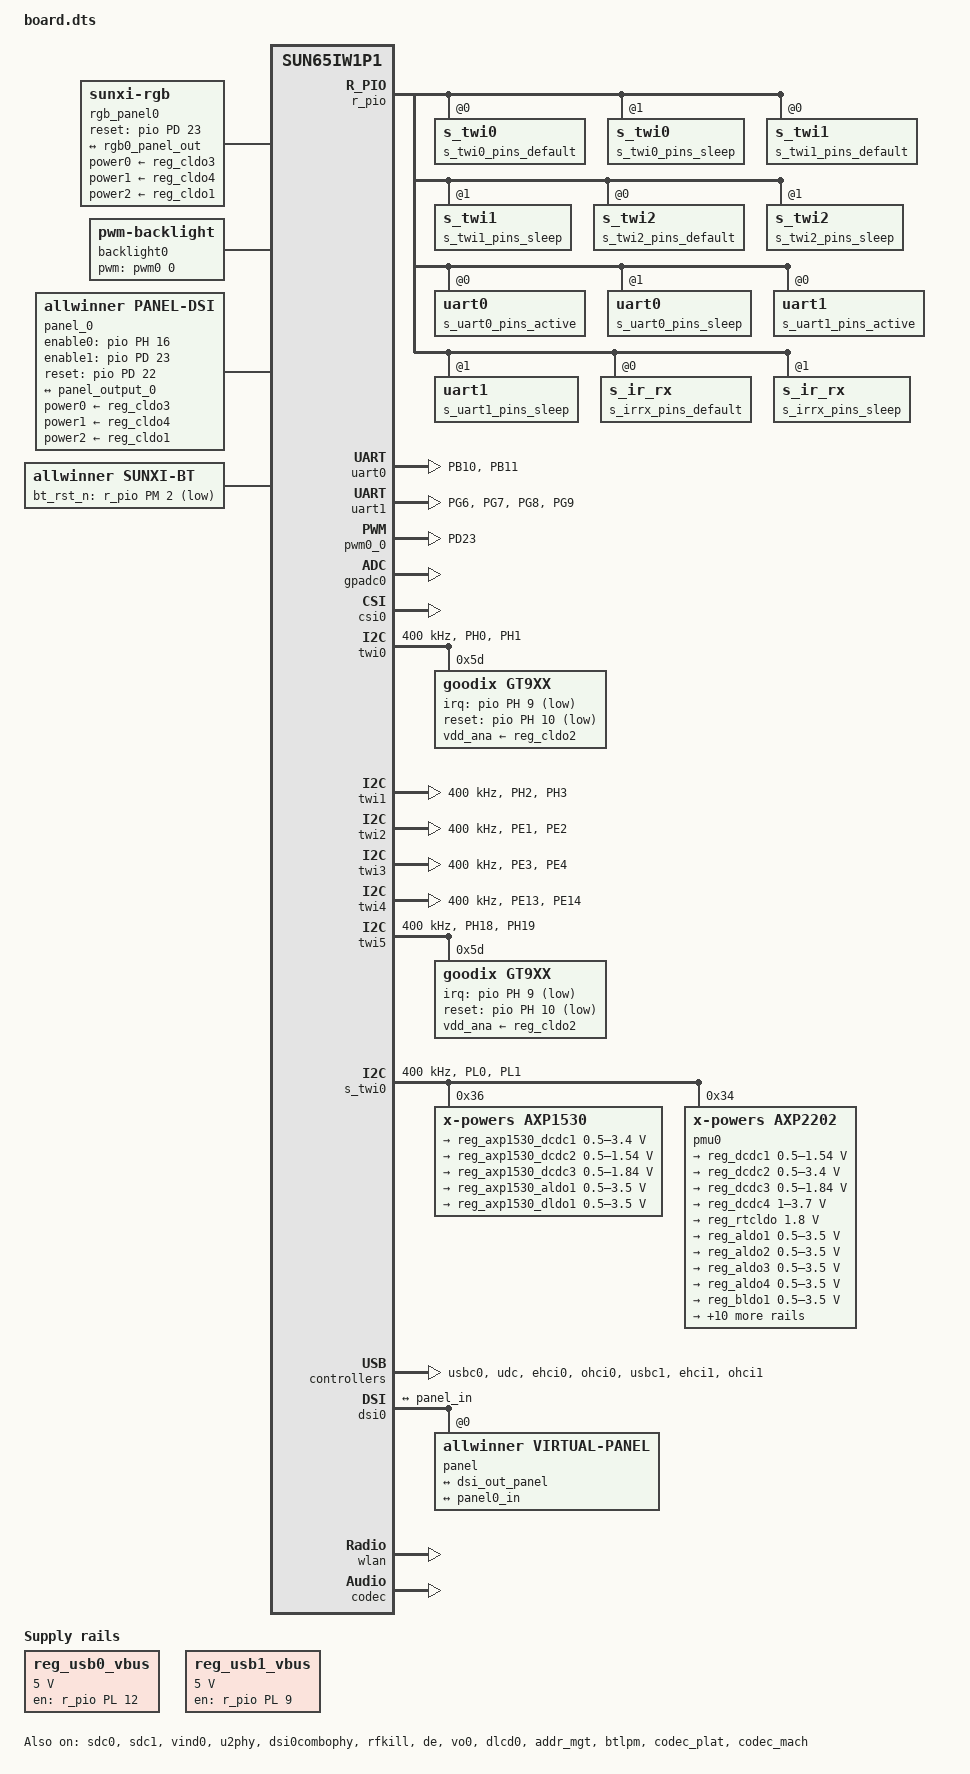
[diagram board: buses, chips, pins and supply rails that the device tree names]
// SPDX-License-Identifier: (GPL-2.0+ or MIT)

/dts-v1/;

#include "sun65iw1p1.dtsi"

/{
	board = "A537", "A537-EVB1";
	compatible = "allwinner,a537", "arm,sun65iw1p1";
	aliases {
	};

	cpus {
		/delete-node/ cpu@2;
		/delete-node/ cpu@3;
		/delete-node/ cpu@201;

		cpu-map {
			cluster0 {
				/delete-node/ core2;
				/delete-node/ core3;
			};

			cluster2 {
				/delete-node/ core1;
			};
		};
	};

	thermal-zones {
		/delete-node/ cpul_idle_zone;

		cpub_idle_zone {
			cooling-maps {
				map0 {
					cooling-device = <&cpu6_idle 0 100>;
				};
			};
		};
	};

	reg_usb0_vbus: usb0-vbus {
		compatible = "regulator-fixed";
		regulator-name = "usb0-vbus";
		regulator-min-microvolt = <5000000>;
		regulator-max-microvolt = <5000000>;
		regulator-enable-ramp-delay = <1000>;
		gpio = <&r_pio PL 12 GPIO_ACTIVE_HIGH>;
		enable-active-high;
	};

	reg_usb1_vbus: usb1-vbus {
		compatible = "regulator-fixed";
		regulator-name = "usb1-vbus";
		regulator-min-microvolt = <5000000>;
		regulator-max-microvolt = <5000000>;
		regulator-enable-ramp-delay = <1000>;
		gpio = <&r_pio PL 9 GPIO_ACTIVE_HIGH>;
		enable-active-high;
	};

	rgb_panel0: rgb_panel@0 {
		compatible = "sunxi-rgb";
		status = "okay";
		reg = <0>;
		power0-supply = <&reg_cldo3>;
		power1-supply = <&reg_cldo4>;
		power2-supply = <&reg_cldo1>;

//		backlight = <&rgb_panel_backlight>;
		reset-gpios = <&pio PD 23 GPIO_ACTIVE_HIGH>; //reset

		display-timings {
			native-mode = <&rgb_timing2>;

			rgb_timing0: timing0 {
				clock-frequency = <74871600>;
				hback-porch = <35>;
				hactive = <1024>;
				hfront-porch = <83>;
				hsync-len = <161>;
				vback-porch = <25>;
				vactive = <600>;
				vfront-porch = <15>;
				vsync-len = <10>;
			};
			rgb_timing1: timing1 {
				clock-frequency = <48360000>;
				hback-porch = <35>;
				hactive = <800>;
				hfront-porch = <385>;
				hsync-len = <20>;
				vback-porch = <25>;
				vactive = <480>;
				vfront-porch = <135>;
				vsync-len = <10>;
			};
			rgb_timing2: timing2 {
				clock-frequency = <29232000>;
				hback-porch = <40>;
				hactive = <800>;
				hfront-porch = <40>;
				hsync-len = <48>;
				vback-porch = <29>;
				vactive = <480>;
				vfront-porch = <13>;
				vsync-len = <3>;
			};
		};
		port {
			rgb0_panel_in: endpoint {
				remote-endpoint = <&rgb0_panel_out>;
			};
		};
	};

	backlight0: backlight0 {
		compatible = "pwm-backlight";
		status = "okay";
		brightness-levels = <
			  0   1   2   3   4   5   6   7
			  8   9  10  11  12  13  14  15
			 16  17  18  19  20  21  22  23
			 24  25  26  27  28  29  30  31
			 32  33  34  35  36  37  38  39
			 40  41  42  43  44  45  46  47
			 48  49  50  51  52  53  54  55
			 56  57  58  59  60  61  62  63
			 64  65  66  67  68  69  70  71
			 72  73  74  75  76  77  78  79
			 80  81  82  83  84  85  86  87
			 88  89  90  91  92  93  94  95
			 96  97  98  99 100 101 102 103
			104 105 106 107 108 109 110 111
			112 113 114 115 116 117 118 119
			120 121 122 123 124 125 126 127
			128 129 130 131 132 133 134 135
			136 137 138 139 140 141 142 143
			144 145 146 147 148 149 150 151
			152 153 154 155 156 157 158 159
			160 161 162 163 164 165 166 167
			168 169 170 171 172 173 174 175
			176 177 178 179 180 181 182 183
			184 185 186 187 188 189 190 191
			192 193 194 195 196 197 198 199
			200 201 202 203 204 205 206 207
			208 209 210 211 212 213 214 215
			216 217 218 219 220 221 222 223
			224 225 226 227 228 229 230 231
			232 233 234 235 236 237 238 239
			240 241 242 243 244 245 246 247
			248 249 250 251 252 253 254 255>;
		default-brightness-level = <73>;
		pwms = <&pwm0 0 25000 0>;
	};

	// lvds_panel: lvds_panel@0 {
	// 	compatible = "sunxi-lvds";
	// 	status = "disabled";
	// 	reg = <0>;
	// 	power0-supply = <&reg_cldo3>;
	// 	power1-supply = <&reg_cldo4>;
	// 	power2-supply = <&reg_cldo1>;
	// //	backlight = <&lvds_panel_backlight>;
	// 	bus-format = <MEDIA_BUS_FMT_RGB888_1X7X4_JEIDA>;
	// 	reset-gpios = <&pio PD 22 GPIO_ACTIVE_HIGH>; //reset
	// 	enable0-gpios = <&pio PH 14 GPIO_ACTIVE_HIGH>; //reset
	// 	display-timings {
	// 		native-mode = <&lvds_timing0>;

	// 		lvds_timing0: timing0 {
	// 			clock-frequency = <69255120>;
	// 			hback-porch = <18>;
	// 			hactive = <1280>;
	// 			hfront-porch = <117>;
	// 			hsync-len = <3>;
	// 			vback-porch = <7>;
	// 			vactive = <800>;
	// 			vfront-porch = <4>;
	// 			vsync-len = <3>;
	// 		};
	// 		lvds_timing1: timing1 {
	// 			clock-frequency = <148500000>;
	// 			hback-porch = <145>;
	// 			hactive = <1920>;
	// 			hfront-porch = <132>;
	// 			hsync-len = <3>;
	// 			vback-porch = <9>;
	// 			vactive = <1080>;
	// 			vfront-porch = <33>;
	// 			vsync-len = <3>;
	// 		};
	// 	};
	// 	port {
	// 		lvds_panel_in: endpoint {
	// 			remote-endpoint = <&lvds_panel_out>;
	// 		};
	// 	};
	// };

	panel_0: panel_0@0 {
		compatible = "allwinner,panel-dsi";
		status = "okay";
		power0-supply = <&reg_cldo3>;
		power1-supply = <&reg_cldo4>;
		power2-supply = <&reg_cldo1>;

		enable0-gpios = <&pio PH 16 GPIO_ACTIVE_HIGH>; // LCD-BL-EN
		enable1-gpios = <&pio PD 23 GPIO_ACTIVE_HIGH>; // LCD-BL-PWM
		reset-num = <2>;
		reset-delay-ms = <10>;
		reset-gpios = <&pio PD 22 GPIO_ACTIVE_HIGH>; // LCD-RST
		dsi,flags = <(MIPI_DSI_MODE_VIDEO | MIPI_DSI_SYNC_INCELL)>;
		dsi,lanes = <4>;
		dsi,format = <0>;
		panel-init-sequence = [
			05 78 01 11
			05 14 01 29
		];

		panel-exit-sequence = [
			05 00 01 28
			05 78 01 10
		];

		display-timings {
			native-mode = <&timing0>;

			timing0: timing0 {
				clock-frequency = <156408000>;
				hback-porch = <40>;
				hactive = <1200>;
				hfront-porch = <80>;
				hsync-len = <10>;
				vback-porch = <16>;
				vactive = <1920>;
				vfront-porch = <20>;
				vsync-len = <4>;

			};
		};
		port {
			panel0_in: endpoint {
				reg = <0>;
				remote-endpoint = <&panel_output_0>;
			};
		};
	};
};

&soc {
	arm_pmu {
		interrupts = <GIC_SPI 316 IRQ_TYPE_LEVEL_HIGH>,
				   <GIC_SPI 317 IRQ_TYPE_LEVEL_HIGH>,
				   <GIC_SPI 348 IRQ_TYPE_LEVEL_HIGH>,
				   <GIC_SPI 349 IRQ_TYPE_LEVEL_HIGH>,
				   <GIC_SPI 374 IRQ_TYPE_LEVEL_HIGH>;
		interrupt-affinity = <&cpu0>, <&cpu1>, <&cpu4>, <&cpu5>, <&cpu6>;
	};
};


&pio {
	uart0_pins_active: uart0_pins@0 {
		pins = "PB10", "PB11";
		function = "uart0";
	};

	uart0_pins_sleep: uart0_pins@1 {
		pins = "PB10", "PB11";
		function = "io_disabled";
	};

	uart1_pins_active: uart1_pins@0 {
		pins = "PG6", "PG7", "PG8", "PG9";
		function = "uart1";
	};

	uart1_pins_sleep: uart1_pins@1 {
		pins = "PG6", "PG7", "PG8", "PG9";
		function = "io_disabled";
	};

	uart2_pins_active: uart2_pins@0 {
		pins = "PB0", "PB1", "PB2", "PB3";
		function = "uart2";
	};

	uart2_pins_sleep: uart2_pins@1 {
		pins = "PB0", "PB1", "PB2", "PB3";
		function = "io_disabled";
	};

	uart3_pins_active: uart3_pins@0 {
		pins = "PH4", "PH5", "PH6", "PH7";
		function = "uart3";
	};

	uart3_pins_sleep: uart3_pins@1 {
		pins = "PH4", "PH5", "PH6", "PH7";
		function = "io_disabled";
	};

	uart4_pins_active: uart4_pins@0 {
		pins = "PE1", "PE2", "PE3", "PE4";
		function = "uart4";
	};

	uart4_pins_sleep: uart4_pins@1 {
		pins = "PE1", "PE2", "PE3", "PE4";
		function = "io_disabled";
	};

	uart5_pins_active: uart5_pins@0 {
		pins = "PE11", "PE12", "PE13", "PE14";
		function = "uart5";
	};

	uart5_pins_sleep: uart5_pins@1 {
		pins = "PE11", "PE12", "PE13", "PE14";
		function = "io_disabled";
	};

	uart6_pins_active: uart6_pins@0 {
		pins = "PH0", "PH1", "PH2", "PH3";
		function = "uart6";
	};

	uart6_pins_sleep: uart6_pins@1 {
		pins = "PH0", "PH1", "PH2", "PH3";
		function = "io_disabled";
	};

	uart7_pins_active: uart7_pins@0 {
		pins = "PE11", "PE12", "PE13", "PE14";
		function = "uart7";
	};

	uart7_pins_sleep: uart7_pins@1 {
		pins = "PE11", "PE12", "PE13", "PE14";
		function = "io_disabled";
	};

	twi0_pins_default: twi0@0 {
		pins = "PH0", "PH1";
		function = "twi0";
		drive-strength = <10>;
		bias-pull-up;
	};

	twi0_pins_sleep: twi0@1 {
		pins = "PH0", "PH1";
		function = "gpio_in";
	};

	twi1_pins_default: twi1@0 {
		pins = "PH2", "PH3";
		function = "twi1";
		drive-strength = <10>;
		bias-pull-up;
	};

	twi1_pins_sleep: twi1@1 {
		pins = "PH2", "PH3";
		function = "gpio_in";
	};

	twi2_pins_default: twi2@0 {
		pins = "PE1", "PE2";
		function = "twi2";
		drive-strength = <10>;
		bias-pull-up;
	};

	twi2_pins_sleep: twi2@1 {
		pins = "PE1", "PE2";
		function = "gpio_in";
	};

	twi3_pins_default: twi3@0 {
		pins = "PE3", "PE4";
		function = "twi3";
		drive-strength = <10>;
		bias-pull-up;
	};

	twi3_pins_sleep: twi3@1 {
		pins = "PE3", "PE4";
		function = "gpio_in";
	};

	twi4_pins_default: twi4@0 {
		pins = "PE13", "PE14";
		function = "twi4";
		drive-strength = <10>;
		bias-pull-up;
	};

	twi4_pins_sleep: twi4@1 {
		pins = "PE13", "PE14";
		function = "gpio_in";
	};

	twi5_pins_default: twi5@0 {
		pins = "PH18", "PH19";
		function = "twi5";
		drive-strength = <10>;
		bias-pull-up;
	};

	twi5_pins_sleep: twi5@1 {
		pins = "PH18", "PH19";
		function = "gpio_in";
	};

	pwm0_0_pins_active: pwm0@0 {
		pins = "PD23";
		function = "pwm0_0";
	};

	pwm0_0_pins_sleep: pwm0@1 {
		pins = "PD23";
		function = "gpio_in";
		bias-pull-down;
	};

	ledc_pins_active: ledc@0 {
		pins = "PH19";
		function = "ledc";
		drive-strength = <10>;
	};

	ledc_pins_sleep: ledc@1 {
		pins = "PH19";
		function = "gpio_in";
	};

	spi1_pins_default: spi1@0 {
		pins = "PD11", "PD12", "PD13"; /* clk, mosi, miso */
		function = "spi1";
		drive-strength = <10>;
	};

	spi1_pins_cs: spi1@1 {
		pins = "PD10"; /* cs */
		function = "spi1";
		drive-strength = <10>;
		bias-pull-up;
	};

	spi1_pins_sleep: spi1@2 {
		pins = "PD10", "PD11", "PD12", "PD13";
		function = "io_disabled";
	};

	irtx_pins_default: irtx@0 {
		pins = "PH18";
		function = "ir_tx";
	};

	irtx_pins_sleep: irtx@1 {
		pins = "PH18";
		function = "gpio_in";
	};

	irrx_pins_default: irrx@0 {
		pins = "PH19";
		function = "ir_rx";
	};

	irrx_pins_sleep: irrx@1 {
		pins = "PH19";
		function = "gpio_in";
	};

	owa_pins_a: owa@0 {
		pins = "PH7";
		function = "owa";
		drive-strength = <20>;
		bias-disable;
	};

	owa_pins_b: owa@1 {
		pins = "PH7";
		function = "io_disabled";
		drive-strength = <20>;
		bias-disable;
	};

	dmic_pins_a: dmic@0 {
		pins = "PH8", "PH9", "PH10", "PH11", "PH12";
		function = "dmic";
		drive-strength = <20>;
		bias-disable;
	};

	dmic_pins_b: dmic@1 {
		pins = "PH8", "PH9", "PH10", "PH11", "PH12";
		function = "io_disabled";
		drive-strength = <20>;
		bias-disable;
	};

	i2s0_pins_a: i2s0@0 {
		pins = "PB4";
		function = "i2s0_mclk";
		drive-strength = <20>;
		bias-disable;
	};

	i2s0_pins_b: i2s0@1 {
		pins = "PB5";
		function = "i2s0_bclk";
		drive-strength = <20>;
		bias-disable;
	};

	i2s0_pins_c: i2s0@2 {
		pins = "PB6";
		function = "i2s0_lrck";
		drive-strength = <20>;
		bias-disable;
	};

	i2s0_pins_d: i2s0@3 {
		pins = "PB8";
		function = "i2s0_din0";
		drive-strength = <20>;
		bias-disable;
	};

	i2s0_pins_e: i2s0@4 {
		pins = "PB4", "PB5", "PB6", "PB8";
		function = "io_disabled";
		drive-strength = <20>;
		bias-disable;
	};

};

&r_pio {
	s_twi0_pins_default: s_twi0@0 {
		pins = "PL0", "PL1";
		function = "s_twi0";
		drive-strength = <10>;
		bias-pull-up;
	};

	s_twi0_pins_sleep: s_twi0@1 {
		pins = "PL0", "PL1";
		function = "gpio_in";
	};

	s_twi1_pins_default: s_twi1@0 {
		pins = "PM2", "PM3";
		function = "s_twi1";
		drive-strength = <10>;
		bias-pull-up;
	};

	s_twi1_pins_sleep: s_twi1@1 {
		pins = "PM2", "PM3";
		function = "gpio_in";
	};

	s_twi2_pins_default: s_twi2@0 {
		pins = "PL12", "PL13";
		function = "s_twi2";
		drive-strength = <10>;
		bias-pull-up;
	};

	s_twi2_pins_sleep: s_twi2@1 {
		pins = "PL12", "PL13";
		function = "gpio_in";
	};

	s_uart0_pins_active: uart0@0 {
		pins = "PL2", "PL3";
		function = "s_uart0";
	};

	s_uart0_pins_sleep: uart0@1 {
		pins = "PL2", "PL3";
		function = "io_disabled";
	};

	s_uart1_pins_active: uart1@0 {
		pins = "PL14", "PL15";
		function = "s_uart1";
	};

	s_uart1_pins_sleep: uart1@1 {
		pins = "PL14", "PL15";
		function = "io_disabled";
	};

	s_irrx_pins_default: s_ir_rx@0 {
		pins = "PM5";
		function = "s_ir";
	};

	s_irrx_pins_sleep: s_ir_rx@1 {
		pins = "PM5";
		function = "gpio_in";
	};
};

&uart0 {
	pinctrl-names = "default", "sleep";
	pinctrl-0 = <&uart0_pins_active>;
	pinctrl-1 = <&uart0_pins_sleep>;
	status = "okay";
};

&uart1 {
	pinctrl-names = "default", "sleep";
	pinctrl-0 = <&uart1_pins_active>;
	pinctrl-1 = <&uart1_pins_sleep>;
	status = "okay";
};

&uart2 {
	pinctrl-names = "default", "sleep";
	pinctrl-0 = <&uart2_pins_active>;
	pinctrl-1 = <&uart2_pins_sleep>;
	status = "disabled";
};

&uart3 {
	pinctrl-names = "default", "sleep";
	pinctrl-0 = <&uart3_pins_active>;
	pinctrl-1 = <&uart3_pins_sleep>;
	status = "disabled";
};

&uart4 {
	pinctrl-names = "default", "sleep";
	pinctrl-0 = <&uart4_pins_active>;
	pinctrl-1 = <&uart4_pins_sleep>;
	status = "disabled";
};

&uart5 {
	pinctrl-names = "default", "sleep";
	pinctrl-0 = <&uart5_pins_active>;
	pinctrl-1 = <&uart5_pins_sleep>;
	status = "disabled";
};

&uart6 {
	pinctrl-names = "default", "sleep";
	pinctrl-0 = <&uart6_pins_active>;
	pinctrl-1 = <&uart6_pins_sleep>;
	status = "disabled";
};

&uart7 {
	pinctrl-names = "default", "sleep";
	pinctrl-0 = <&uart7_pins_active>;
	pinctrl-1 = <&uart7_pins_sleep>;
	status = "disabled";
};

&uart8 {
	pinctrl-names = "default", "sleep";
	pinctrl-0 = <&s_uart0_pins_active>;
	pinctrl-1 = <&s_uart0_pins_sleep>;
	status = "disabled";
};

&uart9 {
	pinctrl-names = "default", "sleep";
	pinctrl-0 = <&s_uart1_pins_active>;
	pinctrl-1 = <&s_uart1_pins_sleep>;
	status = "disabled";
};

&pwm0_0 {
	pinctrl-names = "active", "sleep";
	pinctrl-0 = <&pwm0_0_pins_active>;
	pinctrl-1 = <&pwm0_0_pins_sleep>;
	status = "okay";
};

&gpadc0 {
		channel_num = <5>;
		channel_select = <0x4>;
		channel_data_select = <0x4>;
		channel_compare_select = <0x4>;
		channel_cld_select = <0x4>;
		channel_chd_select = <0x4>;
		channel2_compare_lowdata = <1700000>;
		channel2_compare_higdata = <1200000>;
		status = "okay";
};

&ledc  {
        pinctrl-names = "default", "sleep";
        pinctrl-0 = <&ledc_pins_active>;
        pinctrl-1 = <&ledc_pins_sleep>;
        led_count = <32>;
        output_mode = "GRB";
        reset_ns = <84>;
        t1h_ns = <800>;
        t1l_ns = <320>;
        t0h_ns = <300>;
        t0l_ns = <800>;
        wait_time0_ns = <84>;
        wait_time1_ns = <84>;
        wait_data_time_ns = <600000>;
        status = "disabled";
};

&sdc2 {
	fixed-emmc-driver-type = <2>;
	non-removable;
	bus-width = <8>;
	mmc-ddr-1_8v;
	mmc-hs200-1_8v;
	mmc-hs400-1_8v;
	no-sdio;
	no-sd;
	ctl-spec-caps = <0x328>;
	cap-mmc-highspeed;
	sunxi-dis-signal-vol-sw;
	mmc-bootpart-noacc;
	/*cap-hsq;*/
	cqe-on;
	ctl-cmdq-md = <0x2>;
	max-frequency = <200000000>;
	vmmc-supply = <&reg_cldo3>;
	/*emmc io vol 1.8v*/
	vqmmc-supply = <&reg_cldo1>;
	status = "disabled";
};

&sdc0 {
	bus-width = <4>;
	cd-gpios = <&pio PF 6 (GPIO_ACTIVE_LOW | GPIO_PULL_UP)>;
	/*non-removable;*/
	/*broken-cd;*/
	/*cd-inverted*/
	/*data3-detect;*/
	/*card-pwr-gpios = <&pio PH 14 1 1 2 0xffffffff>;*/
	cd-used-24M;
	cd-set-debounce = <0x1>;
	cap-sd-highspeed;
	sd-uhs-sdr50;
	sd-uhs-ddr50;
	sd-uhs-sdr104;
	no-sdio;
	no-mmc;
	sunxi-power-save-mode;
	/*sunxi-dis-signal-vol-sw;*/
	max-frequency = <150000000>;
	ctl-spec-caps = <0x428>;
	vmmc-supply = <&reg_cldo3>;
	vqmmc33sw-supply = <&reg_cldo3>;
	vdmmc33sw-supply = <&reg_cldo3>;
	vqmmc18sw-supply = <&reg_cldo1>;
	vdmmc18sw-supply = <&reg_cldo1>;
	status = "okay";
};

&sdc1 {
	bus-width = <4>;
	no-mmc;
	no-sd;
	cap-sd-highspeed;
	/*sd-uhs-sdr12*/
	sd-uhs-sdr25;
	sd-uhs-sdr50;
	sd-uhs-ddr50;
	sd-uhs-sdr104;
	/*sunxi-power-save-mode;*/
	sunxi-dis-signal-vol-sw;
	cap-sdio-irq;
	keep-power-in-suspend;
	ignore-pm-notify;
	/*
	 * For AIC Wi-Fi SDIO3.0,
	 * when max-frequency = <208000000>, set sunxi-dly-208M = <0 0 0 0 0 0>
	 * when max-frequency = <150000000>, set sunxi-dly-208M = <1 1 0 0 1 1>
	 */
	max-frequency = <208000000>;
	sunxi-dly-208M  = <0 0 0 0 0 0>;
	ctl-spec-caps = <0x428>;
	status = "okay";
};

&vind0 {
	csi_top = <540000000>;
	csi_isp = <504000000>;
	vind_mclkpin-supply = <&reg_aldo2>; /* vcc-pe */
	vind_mclkpin_vol = <1800000>;
	vind_mcsipin-supply = <&reg_cldo1>; /* vcc-pk */
	vind_mcsipin_vol = <1800000>;
	vind_mipipin-supply = <&reg_cldo1>; /* vcc-mcsi */
	vind_mipipin_vol = <1800000>;

	status = "okay";

	csi0: csi@4820000  {
		pinctrl-0 = <>;
		pinctrl-1 = <>;
		status = "okay";
	};

	tdm0: tdm@4908000 {
		work_mode = <1>;
	};

	isp00:isp@4900000 {
		work_mode = <1>;
	};

	isp01:isp@48ffffc {
		status = "okay";
	};

	isp02:isp@48ffff8 {
		status = "disabled";
	};

	isp03:isp@48ffff4 {
		status = "disabled";
	};

	isp10:isp@4 {
		status = "disabled";
	};

	isp20:isp@5 {
		status = "disabled";
	};

	isp30:isp@6 {
		status = "disabled";
	};

	scaler00:scaler@4910000 {
		work_mode = <1>;
	};

	scaler01:scaler@490fffc {
		status = "okay";
	};

	scaler02:scaler@490fff8 {
		status = "okay";
	};

	scaler03:scaler@490fff4 {
		status = "disabled";
	};

	scaler10:scaler@4910400 {
		work_mode = <1>;
	};

	scaler11:scaler@49103fc {
		status = "okay";
	};

	scaler12:scaler@49103f8 {
		status = "okay";
	};

	scaler13:scaler@49103f4 {
		status = "disabled";
	};

	scaler20:scaler@4910800 {
		work_mode = <1>;
	};

	scaler21:scaler@49107fc {
		status = "disabled";
	};

	scaler22:scaler@49107f8 {
		status = "disabled";
	};

	scaler23:scaler@49107f4 {
		status = "disabled";
	};

	scaler30:scaler@4910c00 {
		work_mode = <1>;
	};

	scaler31:scaler@4910bfc {
		status = "disabled";
	};

	scaler32:scaler@4910bf8 {
		status = "disabled";
	};

	scaler33:scaler@4910bf4 {
		status = "disabled";
	};

	actuator0: actuator@2108180 {
		device_type = "actuator0";
		actuator0_name = "cn3927_act";
		actuator0_slave = <0x18>;
		actuator0_af_pwdn = <>;
		actuator0_afvdd = "afvcc-csi";
		actuator0_afvdd_vol = <2800000>;
		status = "okay";
	};

	flash0: flash@2108190 {
		device_type = "flash0";
		flash0_type = <2>;
		flash0_en = <&r_pio PL 8 GPIO_ACTIVE_LOW>;
		flash0_mode = <>;
		flash0_flvdd = "";
		flash0_flvdd_vol = <>;
		device_id = <0>;
		status = "disabled";
	};

	sensor0: sensor@4812000 {
		device_type = "sensor0";
		sensor0_mname = "ov8856_mipi_2";
		sensor0_twi_cci_id = <2>;
		sensor0_twi_addr = <0x6c>;
		sensor0_mclk_id = <0>;
		sensor0_pos = "rear";
		sensor0_isp_used = <1>;
		sensor0_fmt = <1>;
		sensor0_stby_mode = <0>;
		sensor0_vflip = <0>;
		sensor0_hflip = <0>;
		sensor0_cameravdd-supply = <&reg_bldo3>;
		sensor0_cameravdd_vol = <2800000>;
		sensor0_iovdd-supply = <&reg_aldo2>;
		sensor0_iovdd_vol = <1800000>;
		sensor0_avdd-supply = <&reg_aldo1>;
		sensor0_avdd_vol = <2800000>;
		sensor0_dvdd-supply = <&reg_bldo4>;
		sensor0_dvdd_vol = <1200000>;
		sensor0_power_en = <>;
		sensor0_reset = <&pio PE 9 GPIO_ACTIVE_LOW>;
		sensor0_pwdn = <&pio PE 8 GPIO_ACTIVE_LOW>;
		status = "okay";
	};

	sensor1: sensor@4812010 {
		device_type = "sensor1";
		sensor1_mname = "gc6153";
		sensor1_twi_cci_id = <3>;
		sensor1_twi_addr = <0x80>;
		sensor1_mclk_id = <1>;
		sensor1_pos = "rear";
		sensor1_isp_used = <1>;
		sensor1_fmt = <1>;
		sensor1_stby_mode = <0>;
		sensor1_vflip = <0>;
		sensor1_hflip = <0>;
		sensor1_iovdd-supply = <&reg_aldo2>;
		sensor1_iovdd_vol = <1800000>;
		sensor1_avdd-supply = <&reg_aldo1>;
		sensor1_avdd_vol = <2800000>;
		sensor1_dvdd-supply = <&reg_bldo4>;
		sensor1_dvdd_vol = <1200000>;
		sensor1_power_en = <>;
		sensor1_reset = <&pio PE 12 GPIO_ACTIVE_LOW>;
		sensor1_pwdn = <&pio PE 11 GPIO_ACTIVE_LOW>;
		status = "disabled";
	};

	sensor2: sensor@4812020 {
		device_type = "sensor2";
		sensor2_mname = "gc05a2_mipi";
		sensor2_twi_cci_id = <2>;
		sensor2_twi_addr = <0x6e>;
		sensor2_mclk_id = <0>;
		sensor2_pos = "front";
		sensor2_isp_used = <1>;
		sensor2_fmt = <1>;
		sensor2_stby_mode = <0>;
		sensor2_vflip = <0>;
		sensor2_hflip = <0>;
		sensor2_iovdd-supply = <&reg_aldo2>;
		sensor2_iovdd_vol = <1800000>;
		sensor2_avdd-supply = <&reg_aldo1>;
		sensor2_avdd_vol = <2800000>;
		sensor2_dvdd-supply = <&reg_bldo4>;
		sensor2_dvdd_vol = <1200000>;
		sensor2_power_en = <>;
		sensor2_reset = <&pio PE 7 GPIO_ACTIVE_LOW>;
		sensor2_pwdn = <&pio PE 6 GPIO_ACTIVE_LOW>;
		status = "okay";
	};

	sensor_list0:sensor_list@4812040 {
		sensor00_mname = "ov8856_mipi_2";
		sensor00_twi_addr = <0x6c>;
		sensor00_type = <1>;
		sensor00_hflip =  <0>;
		sensor00_vflip = <0>;
		sensor00_act_used = <1>;
		sensor00_act_name = "cn3927_act";
		sensor00_act_twi_addr = <0x18>;
		sensor01_mname = "ov13b10_mipi";
		sensor01_twi_addr = <0x6c>;
		sensor01_type = <1>;
		sensor01_hflip = <0>;
		sensor01_vflip = <0>;
		sensor01_act_used = <1>;
		sensor01_act_name = "cn3927_act";
		sensor01_act_twi_addr = <0x18>;
		sensor02_mname = "";
		sensor02_twi_addr = <>;
		sensor02_type = <>;
		sensor02_hflip =  <>;
		sensor02_vflip = <>;
		sensor02_act_used = <>;
		sensor02_act_name = "";
		sensor02_act_twi_addr = <>;
		status = "okay";
	};

	sensor_list1:sensor_list@4812050 {
		sensor10_mname = "gc6153";
		sensor10_twi_addr = <0x80>;
		sensor10_type = <1>;
		sensor10_hflip =  <0>;
		sensor10_vflip = <0>;
		sensor10_act_used = <0>;
		sensor10_act_name = "";
		sensor10_act_twi_addr = <>;
		sensor11_mname = "";
		sensor11_twi_addr = <>;
		sensor11_type = <>;
		sensor11_hflip =  <>;
		sensor11_vflip = <>;
		sensor11_act_used = <>;
		sensor11_act_name = "";
		sensor11_act_twi_addr = <>;
		sensor12_mname = "";
		sensor12_twi_addr = <>;
		sensor12_type = <>;
		sensor12_hflip =  <>;
		sensor12_vflip = <>;
		sensor12_act_used = <>;
		sensor12_act_name = "";
		sensor12_act_twi_addr = <>;
		status = "disabled";
	};

	sensor_list2:sensor_list@4812060 {
		reg = <0x0 0x04812060 0x0 0x10>;
		device_type = "sensor_list2";
		compatible = "allwinner,sunxi-sensor-list";
		csi_sel = <0>;
		sensor20_mname = "gc05a2_mipi";
		sensor20_twi_addr = <0x6e>;
		sensor20_type = <1>;
		sensor20_hflip =  <0>;
		sensor20_vflip = <0>;
		sensor20_act_used = <0>;
		sensor20_act_name = "";
		sensor20_act_twi_addr = <>;
		sensor21_mname = "";
		sensor21_twi_addr = <>;
		sensor21_type = <>;
		sensor21_hflip =  <>;
		sensor21_vflip = <>;
		sensor21_act_used = <>;
		sensor21_act_name = "";
		sensor21_act_twi_addr = <>;
		sensor22_mname = "";
		sensor22_twi_addr = <>;
		sensor22_type = <>;
		sensor22_hflip =  <>;
		sensor22_vflip = <>;
		sensor22_act_used = <>;
		sensor22_act_name = "";
		sensor22_act_twi_addr = <>;
		device_id = <1>;
		status = "okay";
	};

	vinc00:vinc@4830000 {
		vinc0_csi_sel = <0>;
		vinc0_mipi_sel = <0>;
		vinc0_isp_sel = <0>;
		vinc0_isp_tx_ch = <0>;
		vinc0_tdm_rx_sel = <0>;
		vinc0_rear_sensor_sel = <0>;
		vinc0_front_sensor_sel = <0>;
		vinc0_sensor_list = <1>;
		device_id = <0>;
		work_mode = <0x1>;
		status = "okay";
	};

	vinc01:vinc@482fffc {
		vinc1_csi_sel = <0>;
		vinc1_mipi_sel = <0>;
		vinc1_isp_sel = <1>;
		vinc1_isp_tx_ch = <0>;
		vinc1_tdm_rx_sel = <1>;
		vinc1_rear_sensor_sel = <0>;
		vinc1_front_sensor_sel = <0>;
		vinc1_sensor_list = <1>;
		device_id = <1>;
		status = "okay";
	};

	vinc02:vinc@482fff8 {
		vinc2_csi_sel = <2>;
		vinc2_mipi_sel = <2>;
		vinc2_isp_sel = <2>;
		vinc2_isp_tx_ch = <0>;
		vinc2_tdm_rx_sel = <2>;
		vinc2_rear_sensor_sel = <1>;
		vinc2_front_sensor_sel = <1>;
		vinc2_sensor_list = <1>;
		device_id = <2>;
		status = "disabled";
	};

	vinc03:vinc@482fff4 {
		vinc3_csi_sel = <0>;
		vinc3_mipi_sel = <0xff>;
		vinc3_isp_sel = <0>;
		vinc3_isp_tx_ch = <0>;
		vinc3_tdm_rx_sel = <0>;
		vinc3_rear_sensor_sel = <1>;
		vinc3_front_sensor_sel = <1>;
		vinc3_sensor_list = <0>;
		device_id = <3>;
		status = "disabled";
	};

	vinc10:vinc@4831000 {
		vinc4_csi_sel = <0>;
		vinc4_mipi_sel = <0>;
		vinc4_isp_sel = <0>;
		vinc4_isp_tx_ch = <0>;
		vinc4_tdm_rx_sel = <0>;
		vinc4_rear_sensor_sel = <0>;
		vinc4_front_sensor_sel = <0>;
		vinc4_sensor_list = <1>;
		device_id = <4>;
		work_mode = <0x1>;
		status = "okay";
	};

	vinc11:vinc@4830ffc {
		vinc5_csi_sel = <0>;
		vinc5_mipi_sel = <0>;
		vinc5_isp_sel = <1>;
		vinc5_isp_tx_ch = <0>;
		vinc5_tdm_rx_sel = <1>;
		vinc5_rear_sensor_sel = <0>;
		vinc5_front_sensor_sel = <0>;
		vinc5_sensor_list = <1>;
		device_id = <5>;
		status = "okay";
	};

	vinc12:vinc@4830ff8 {
		vinc6_csi_sel = <2>;
		vinc6_mipi_sel = <2>;
		vinc6_isp_sel = <2>;
		vinc6_isp_tx_ch = <0>;
		vinc6_tdm_rx_sel = <2>;
		vinc6_rear_sensor_sel = <1>;
		vinc6_front_sensor_sel = <1>;
		vinc6_sensor_list = <1>;
		device_id = <6>;
		status = "disabled";
	};

	vinc13:vinc@4830ff4 {
		vinc7_csi_sel = <2>;
		vinc7_mipi_sel = <0xff>;
		vinc7_isp_sel = <0>;
		vinc7_isp_tx_ch = <0>;
		vinc7_tdm_rx_sel = <0>;
		vinc7_rear_sensor_sel = <0>;
		vinc7_front_sensor_sel = <0>;
		vinc7_sensor_list = <0>;
		device_id = <7>;
		status = "disabled";
	};

	vinc20:vinc@4832000 {
		vinc8_csi_sel = <1>;
		vinc8_mipi_sel = <1>;
		vinc8_isp_sel = <0>;
		vinc8_isp_tx_ch = <0>;
		vinc8_tdm_rx_sel = <0>;
		vinc8_rear_sensor_sel = <2>;
		vinc8_front_sensor_sel = <2>;
		vinc8_sensor_list = <1>;
		device_id = <8>;
		work_mode = <0x1>;
		status = "okay";
	};

	vinc21:vinc@4831ffc {
		vinc9_csi_sel = <2>;
		vinc9_mipi_sel = <0xff>;
		vinc9_isp_sel = <0>;
		vinc9_isp_tx_ch = <0>;
		vinc9_tdm_rx_sel = <0>;
		vinc9_rear_sensor_sel = <0>;
		vinc9_front_sensor_sel = <0>;
		vinc9_sensor_list = <0>;
		device_id = <9>;
		status = "disabled";
	};

	vinc22:vinc@4831ff8 {
		vinc10_csi_sel = <2>;
		vinc10_mipi_sel = <0xff>;
		vinc10_isp_sel = <0>;
		vinc10_isp_tx_ch = <0>;
		vinc10_tdm_rx_sel = <0>;
		vinc10_rear_sensor_sel = <0>;
		vinc10_front_sensor_sel = <0>;
		vinc10_sensor_list = <0>;
		device_id = <10>;
		status = "disabled";
	};

	vinc23:vinc@4831ff4 {
		vinc11_csi_sel = <2>;
		vinc11_mipi_sel = <0xff>;
		vinc11_isp_sel = <0>;
		vinc11_isp_tx_ch = <0>;
		vinc11_tdm_rx_sel = <0>;
		vinc11_rear_sensor_sel = <0>;
		vinc11_front_sensor_sel = <0>;
		vinc11_sensor_list = <0>;
		device_id = <11>;
		status = "disabled";
	};

	vinc30:vinc@4833000 {
		vinc12_csi_sel = <1>;
		vinc12_mipi_sel = <1>;
		vinc12_isp_sel = <0>;
		vinc12_isp_tx_ch = <0>;
		vinc12_tdm_rx_sel = <0>;
		vinc12_rear_sensor_sel = <2>;
		vinc12_front_sensor_sel = <2>;
		vinc12_sensor_list = <1>;
		device_id = <12>;
		work_mode = <0x1>;
		status = "okay";
	};

	vinc31:vinc@4832ffc {
		vinc13_csi_sel = <2>;
		vinc13_mipi_sel = <0xff>;
		vinc13_isp_sel = <0>;
		vinc13_isp_tx_ch = <0>;
		vinc13_tdm_rx_sel = <0>;
		vinc13_rear_sensor_sel = <0>;
		vinc13_front_sensor_sel = <0>;
		vinc13_sensor_list = <0>;
		device_id = <13>;
		status = "disabled";
	};

	vinc32:vinc@4832ff8 {
		vinc14_csi_sel = <2>;
		vinc14_mipi_sel = <0xff>;
		vinc14_isp_sel = <0>;
		vinc14_isp_tx_ch = <0>;
		vinc14_tdm_rx_sel = <0>;
		vinc14_rear_sensor_sel = <0>;
		vinc14_front_sensor_sel = <0>;
		vinc14_sensor_list = <0>;
		device_id = <14>;
		status = "disabled";
	};

	vinc33:vinc@4832ff4 {
		vinc15_csi_sel = <2>;
		vinc15_mipi_sel = <0xff>;
		vinc15_isp_sel = <0>;
		vinc15_isp_tx_ch = <0>;
		vinc15_tdm_rx_sel = <0>;
		vinc15_rear_sensor_sel = <0>;
		vinc15_front_sensor_sel = <0>;
		vinc15_sensor_list = <0>;
		device_id = <15>;
		status = "disabled";
	};
};

&twi0 {
	clock-frequency = <400000>;
	pinctrl-0 = <&twi0_pins_default>;
	pinctrl-1 = <&twi0_pins_sleep>;
	pinctrl-names = "default", "sleep";
	/* For stability and backwards compatibility, we recommend setting 'twi_drv_used' to 1 */
	twi_drv_used = <1>;
	/* twi-supply = <&reg_cldo3>; */
	status = "okay";

	ac107: ac107@36 {
		#sound-dai-cells        = <0>;
		compatible              = "allwinner,sunxi-ac107";
		reg                     = <0x36>;
		pllclk-src              = "MCLK";
		sysclk-src              = "MCLK";
		pcm-bit-first           = "MSB";
		frame-sync-width        = <1>;
		tx-pin-chmap0           = <0x10101010>;
		tx-pin-chmap1           = <0x10101010>;
		ch1-dig-vol             = <160>;
		ch2-dig-vol             = <160>;
		ch1-pga-gain            = <26>;
		ch2-pga-gain            = <26>;
		status                  = "disabled";
	};

	gt9xx {
		compatible = "goodix,gt9xx";
		reg = <0x5d>;
		status = "okay";
		irq-gpios = <&pio PH 9 GPIO_ACTIVE_LOW>;
		irq-flags = <2>;
		reset-gpios = <&pio PH 10 GPIO_ACTIVE_LOW>;
		vdd_ana-supply = <&reg_cldo2>;

		touchscreen-max-id = <11>;
		touchscreen-size-x = <1200>;
		touchscreen-size-y = <1920>;
		touchscreen-max-w = <512>;
		touchscreen-max-p = <512>;
		//touchscreen-key-map = <172>, <158>; /*KEY_HOMEPAGE=172, KEY_BACK=158，KEY_MENU=139*/
		goodix,slide-wakeup = <0>;
		goodix,type-a-report = <1>;
		goodix,driver-send-cfg = <0>;
		goodix,send-cfg-id = <0>;
		goodix,resume-in-workqueue = <0>;
		goodix,int-sync = <1>;
		goodix,revert_x = <1>;
		goodix,revert_y = <1>;
		goodix,swap-x2y = <0>;
		goodix,tp_idle_support = <1>;
		goodix,esd-protect = <1>;
		goodix,auto-update-cfg = <0>;
		goodix,power-off-sleep = <1>;
		goodix,pen-suppress-finger = <0>;
		/* GT9271_Config_20221222_v67.cfg*/
		goodix,cfg-group0 = [
			43 B0 04 80 07 0A 35 00 01 08
			28 0F 50 32 03 05 00 00 00 00
			00 00 00 17 19 1B 14 90 2B 99
			2F 31 8E 12 00 00 00 DA 03 10
			00 00 00 00 00 00 00 00 00 11
			00 29 4B 94 C5 02 07 00 00 04
			85 2B 00 7D 31 00 77 37 00 72
			3E 00 6F 46 00 6F 00 00 00 00
			00 00 00 00 00 00 00 00 00 00
			00 00 00 00 00 00 00 00 00 00
			00 00 00 00 C0 00 00 00 00 00
			00 00 17 16 15 14 11 10 0F 0E
			0D 0C 09 08 07 06 05 04 01 00
			FF FF FF FF FF FF 00 00 00 00
			00 00 25 24 23 22 21 20 1F 1E
			1C 1B 19 14 13 12 11 10 0F 0E
			0D 0C 0A 08 07 06 04 02 00 FF
			FF FF FF FF 00 00 00 00 00 00
			00 00 00 00 73 01
		];
	};
};

&twi1 {
	clock-frequency = <400000>;
	pinctrl-0 = <&twi1_pins_default>;
	pinctrl-1 = <&twi1_pins_sleep>;
	pinctrl-names = "default", "sleep";
	/* For stability and backwards compatibility, we recommend setting 'twi_drv_used' to 1 */
	twi_drv_used = <1>;
	/* twi-supply = <&reg_cldo3>; */
	status = "okay";
};

&twi2 {
	clock-frequency = <400000>;
	pinctrl-0 = <&twi2_pins_default>;
	pinctrl-1 = <&twi2_pins_sleep>;
	pinctrl-names = "default", "sleep";
	/* For stability and backwards compatibility, we recommend setting 'twi_drv_used' to 1 */
	twi_drv_used = <1>;
	/* twi-supply = <&reg_aldo2>; */
	status = "okay";
};

&twi3 {
	clock-frequency = <400000>;
	pinctrl-0 = <&twi3_pins_default>;
	pinctrl-1 = <&twi3_pins_sleep>;
	pinctrl-names = "default", "sleep";
	/* For stability and backwards compatibility, we recommend setting 'twi_drv_used' to 1 */
	twi_drv_used = <1>;
	/* twi-supply = <&reg_aldo2>; */
	status = "okay";
};

&twi4 {
	clock-frequency = <400000>;
	pinctrl-0 = <&twi4_pins_default>;
	pinctrl-1 = <&twi4_pins_sleep>;
	pinctrl-names = "default", "sleep";
	/* For stability and backwards compatibility, we recommend setting 'twi_drv_used' to 1 */
	twi_drv_used = <1>;
	/* twi-supply = <&reg_aldo2>; */
	status = "okay";
};

&twi5 {
	clock-frequency = <400000>;
	pinctrl-0 = <&twi5_pins_default>;
	pinctrl-1 = <&twi5_pins_sleep>;
	pinctrl-names = "default", "sleep";
	/* For stability and backwards compatibility, we recommend setting 'twi_drv_used' to 1 */
	twi_drv_used = <1>;
	twi-supply = <&reg_cldo3>;
	status = "okay";

	gt9xx {
		compatible = "goodix,gt9xx";
		reg = <0x5d>;
		status = "okay";
		irq-gpios = <&pio PH 9 GPIO_ACTIVE_LOW>;
		irq-flags = <2>;
		reset-gpios = <&pio PH 10 GPIO_ACTIVE_LOW>;
		vdd_ana-supply = <&reg_cldo2>;

		touchscreen-max-id = <11>;
		touchscreen-size-x = <1200>;
		touchscreen-size-y = <1920>;
		touchscreen-max-w = <512>;
		touchscreen-max-p = <512>;
		//touchscreen-key-map = <172>, <158>; /*KEY_HOMEPAGE=172, KEY_BACK=158，KEY_MENU=139*/
		goodix,slide-wakeup = <0>;
		goodix,type-a-report = <1>;
		goodix,driver-send-cfg = <0>;
		goodix,send-cfg-id = <0>;
		goodix,resume-in-workqueue = <0>;
		goodix,int-sync = <1>;
		goodix,revert_x = <1>;
		goodix,revert_y = <1>;
		goodix,swap-x2y = <0>;
		goodix,tp_idle_support = <1>;
		goodix,esd-protect = <1>;
		goodix,auto-update-cfg = <0>;
		goodix,power-off-sleep = <1>;
		goodix,pen-suppress-finger = <0>;
		/* GT9271_Config_20221222_v67.cfg*/
		goodix,cfg-group0 = [
			43 B0 04 80 07 0A 35 00 01 08
			28 0F 50 32 03 05 00 00 00 00
			00 00 00 17 19 1B 14 90 2B 99
			2F 31 8E 12 00 00 00 DA 03 10
			00 00 00 00 00 00 00 00 00 11
			00 29 4B 94 C5 02 07 00 00 04
			85 2B 00 7D 31 00 77 37 00 72
			3E 00 6F 46 00 6F 00 00 00 00
			00 00 00 00 00 00 00 00 00 00
			00 00 00 00 00 00 00 00 00 00
			00 00 00 00 C0 00 00 00 00 00
			00 00 17 16 15 14 11 10 0F 0E
			0D 0C 09 08 07 06 05 04 01 00
			FF FF FF FF FF FF 00 00 00 00
			00 00 25 24 23 22 21 20 1F 1E
			1C 1B 19 14 13 12 11 10 0F 0E
			0D 0C 0A 08 07 06 04 02 00 FF
			FF FF FF FF 00 00 00 00 00 00
			00 00 00 00 73 01
		];
	};

};

&s_twi0 {
	clock-frequency = <400000>;
	pinctrl-0 = <&s_twi0_pins_default>;
	pinctrl-1 = <&s_twi0_pins_sleep>;
	pinctrl-names = "default", "sleep";
	/* For stability and backwards compatibility, we recommend setting 'twi_drv_used' to 1 */
	twi_drv_used = <1>;
	/* twi-supply = <&reg_aldo3>; */
	no_suspend = <1>;
	status = "okay";

	axp1530: axp1530@36{
		compatible = "x-powers,axp1530";
		status = "okay";
		reg = <0x36>;

		powerkey1: powerkey@1 {
			status = "disabled";
			compatible = "x-powers,axp1530-pek";
		};

		regulators{
			compatible = "x-powers,axp1530-regulator";
			reg_axp1530_dcdc1: dcdc1 {
				regulator-name = "axp1530-dcdc1";
				regulator-min-microvolt = <500000>;
				regulator-max-microvolt = <3400000>;
				regulator-step-delay-us = <25>;
				regulator-final-delay-us = <50>;
				regulator-always-on;
			};

			reg_axp1530_dcdc2: dcdc2 {
				regulator-name = "axp1530-dcdc2";
				regulator-min-microvolt = <500000>;
				regulator-max-microvolt = <1540000>;
				regulator-step-delay-us = <25>;
				regulator-final-delay-us = <50>;
				regulator-always-on;
			};

			reg_axp1530_dcdc3: dcdc3 {
				regulator-name = "axp1530-dcdc3";
				regulator-min-microvolt = <500000>;
				regulator-max-microvolt = <1840000>;
				regulator-step-delay-us = <25>;
				regulator-final-delay-us = <50>;
			};

			reg_axp1530_aldo1: ldo1 {
				regulator-name = "axp1530-aldo1";
				regulator-min-microvolt = <500000>;
				regulator-max-microvolt = <3500000>;
				regulator-step-delay-us = <25>;
				regulator-final-delay-us = <50>;
			};

			reg_axp1530_dldo1: ldo2 {
				regulator-name = "axp1530-dldo1";
				regulator-min-microvolt = <500000>;
				regulator-max-microvolt = <3500000>;
				regulator-step-delay-us = <25>;
				regulator-final-delay-us = <50>;
			};
		};
		virtual-ext-dcdc1 {
			compatible = "xpower-vregulator,dcdc1";
			dcdc1-supply = <&reg_axp1530_dcdc1>;
		};
		virtual-ext-dcdc2 {
			compatible = "xpower-vregulator,dcdc2";
			dcdc2-supply = <&reg_axp1530_dcdc2>;
		};
		virtual-ext-dcdc3 {
			compatible = "xpower-vregulator,dcdc3";
			dcdc3-supply = <&reg_axp1530_dcdc3>;
		};
		virtual-ext-aldo1 {
			compatible = "xpower-vregulator,aldo1";
			aldo1-supply = <&reg_axp1530_aldo1>;
		};
		virtual-ext-dldo1 {
			compatible = "xpower-vregulator,dldo1";
			dldo1-supply = <&reg_axp1530_dldo1>;
		};

	};
	pmu0: pmu@34 {
		compatible = "x-powers,axp2202";
		reg = <0x34>;
		status = "okay";
		interrupts = <0 IRQ_TYPE_LEVEL_LOW>;
		interrupt-parent = <&nmi_intc>;
		x-powers,drive-vbus-en;
		pmu_reset = <0>;
		pmu_irq_wakeup = <1>;
		pmu_hot_shutdown = <1>;

		wakeup-source;

		usb_power_supply: usb_power_supply {
			compatible = "x-powers,axp2202-usb-power-supply";
			status = "okay";

			pmu_usbpc_vol = <4600>;
			pmu_usbpc_cur = <500>;
			pmu_usbad_vol = <4000>;
			pmu_usbad_cur = <2500>;
			pmu_usb_typec_used = <1>;
			wakeup_usb_in;
			wakeup_usb_out;
			wakeup_typec_in;
			wakeup_typec_out;

			det_acin_supply = <&gpio_power_supply>;
			pmu_acin_usbid_drv = <&pio PH 12 GPIO_ACTIVE_LOW>;
			pmu_vbus_det_gpio = <&pio PH 13 GPIO_ACTIVE_LOW>;
		};

		gpio_power_supply: gpio_power_supply {
			compatible = "x-powers,gpio-supply";
			status = "disabled";
			pmu_acin_det_gpio = <&pio PH 14 GPIO_ACTIVE_LOW>;
			det_usb_supply = <&usb_power_supply>;
		};

		bat_power_supply: bat-power-supply {
			compatible = "x-powers,axp2202-bat-power-supply";
			param = <&axp2202_parameter>;
			status = "disabled";

			pmu_chg_ic_temp = <0>;

			pmu_battery_rdc= <170>;
			pmu_battery_cap = <5000>;
			pmu_runtime_chgcur = <1000>;
			pmu_suspend_chgcur = <1500>;
			pmu_shutdown_chgcur = <1500>;
			pmu_init_chgvol = <4350>;
			pmu_battery_warning_level1 = <15>;
			pmu_battery_warning_level2 = <0>;
			pmu_chgled_func = <0>;
			pmu_chgled_type = <0>;
			pmu_bat_para1 = <0>;
			pmu_bat_para2 = <0>;
			pmu_bat_para3 = <0>;
			pmu_bat_para4 = <0>;
			pmu_bat_para5 = <0>;
			pmu_bat_para6 = <0>;
			pmu_bat_para7 = <2>;
			pmu_bat_para8 = <3>;
			pmu_bat_para9 = <4>;
			pmu_bat_para10 = <6>;
			pmu_bat_para11 = <9>;
			pmu_bat_para12 = <14>;
			pmu_bat_para13 = <26>;
			pmu_bat_para14 = <38>;
			pmu_bat_para15 = <49>;
			pmu_bat_para16 = <52>;
			pmu_bat_para17 = <56>;
			pmu_bat_para18 = <60>;
			pmu_bat_para19 = <64>;
			pmu_bat_para20 = <70>;
			pmu_bat_para21 = <77>;
			pmu_bat_para22 = <83>;
			pmu_bat_para23 = <87>;
			pmu_bat_para24 = <90>;
			pmu_bat_para25 = <95>;
			pmu_bat_para26 = <99>;
			pmu_bat_para27 = <99>;
			pmu_bat_para28 = <100>;
			pmu_bat_para29 = <100>;
			pmu_bat_para30 = <100>;
			pmu_bat_para31 = <100>;
			pmu_bat_para32 = <100>;

			pmu_bat_temp_enable = <1>;
			pmu_jetia_en        = <1>;
			pmu_bat_charge_ltf = <1695>; //-5
			pmu_bat_charge_htf = <151>; //60
			pmu_bat_shutdown_ltf = <2125>; //-10
			pmu_bat_shutdown_htf = <131>; //65
			pmu_jetia_cool = <1361>; //0
			pmu_jetia_warm = <208>; //50
			pmu_jcool_ifall = <0>;//100%
			pmu_jwarm_ifall = <0>;//100%
			pmu_bat_temp_para1 = <4378>; //Murata -25
			pmu_bat_temp_para2 = <2682>; //-15
			pmu_bat_temp_para3 = <2125>; //-10
			pmu_bat_temp_para4 = <1695>; //-5
			pmu_bat_temp_para5 = <1361>;//0
			pmu_bat_temp_para6 = <1101>; //5
			pmu_bat_temp_para7 = <896>; //10
			pmu_bat_temp_para8 = <604>; //20
			pmu_bat_temp_para9 = <416>; //30
			pmu_bat_temp_para10 = <292>; //40
			pmu_bat_temp_para11 = <246>; //45
			pmu_bat_temp_para12 = <208>; //50
			pmu_bat_temp_para13 = <177>; //55
			pmu_bat_temp_para14 = <151>; //60
			pmu_bat_temp_para15 = <111>; //70
			pmu_bat_temp_para16 = <83>; //80

			wakeup_bat_out;
			wakeup_new_soc;
			/* wakeup_bat_in; */
			/* wakeup_bat_charging; */
			/* wakeup_bat_charge_over; */
			/* wakeup_low_warning1; */
			/* wakeup_low_warning2; */
			wakeup_bat_untemp_work;
			wakeup_bat_ovtemp_work;
			/* wakeup_bat_untemp_chg; */
			/* wakeup_bat_ovtemp_chg; */
		};

		powerkey0: powerkey@0 {
			status = "okay";
			compatible = "x-powers,axp2101-pek";
			pmu_powkey_off_time = <6000>;
			pmu_powkey_off_func = <0>;
			pmu_powkey_off_en = <1>;
			pmu_powkey_long_time = <1500>;
			pmu_powkey_on_time = <512>;
			wakeup_rising;
			wakeup_falling;
		};

		regulator0: regulators@0 {
			reg_dcdc1: dcdc1 {
				regulator-name = "axp2202-dcdc1";
				regulator-min-microvolt = <500000>;
				regulator-max-microvolt = <1540000>;
				regulator-ramp-delay = <250>;
				regulator-enable-ramp-delay = <1000>;
				regulator-boot-on;
				regulator-always-on;
			};
			reg_dcdc2: dcdc2 {
				regulator-name = "axp2202-dcdc2";
				regulator-min-microvolt = <500000>;
				regulator-max-microvolt = <3400000>;
				regulator-ramp-delay = <250>;
				regulator-enable-ramp-delay = <1000>;
				regulator-boot-on;
				regulator-always-on;
			};
			reg_dcdc3: dcdc3 {
				regulator-name = "axp2202-dcdc3";
				regulator-min-microvolt = <500000>;
				regulator-max-microvolt = <1840000>;
				regulator-ramp-delay = <250>;
				regulator-enable-ramp-delay = <1000>;
				regulator-always-on;
			};
			reg_dcdc4: dcdc4 {
				regulator-name = "axp2202-dcdc4";
				regulator-min-microvolt = <1000000>;
				regulator-max-microvolt = <3700000>;
				regulator-ramp-delay = <250>;
				regulator-enable-ramp-delay = <1000>;
			};
			reg_rtcldo: rtcldo {
				/* RTC_LDO is a fixed, always-on regulator */
				regulator-name = "axp2202-rtcldo";
				regulator-min-microvolt = <1800000>;
				regulator-max-microvolt = <1800000>;
				regulator-boot-on;
				regulator-always-on;
			};
			reg_aldo1: aldo1 {
				regulator-name = "axp2202-aldo1";
				regulator-min-microvolt = <500000>;
				regulator-max-microvolt = <3500000>;
				regulator-ramp-delay = <500>;
				regulator-enable-ramp-delay = <1000>;
			};
			reg_aldo2: aldo2 {
				regulator-name = "axp2202-aldo2";
				regulator-min-microvolt = <500000>;
				regulator-max-microvolt = <3500000>;
				regulator-ramp-delay = <500>;
				regulator-enable-ramp-delay = <1000>;
			};
			reg_aldo3: aldo3 {
				regulator-name = "axp2202-aldo3";
				regulator-min-microvolt = <500000>;
				regulator-max-microvolt = <3500000>;
				regulator-ramp-delay = <500>;
				regulator-enable-ramp-delay = <1000>;
				regulator-always-on;
				regulator-boot-on;
			};
			reg_aldo4: aldo4 {
				regulator-name = "axp2202-aldo4";
				regulator-min-microvolt = <500000>;
				regulator-max-microvolt = <3500000>;
				regulator-ramp-delay = <500>;
				regulator-enable-ramp-delay = <1000>;
				regulator-always-on;
				regulator-boot-on;
			};
			reg_bldo1: bldo1 {
				regulator-name = "axp2202-bldo1";
				regulator-min-microvolt = <500000>;
				regulator-max-microvolt = <3500000>;
				regulator-ramp-delay = <500>;
				regulator-enable-ramp-delay = <1000>;
			};
			reg_bldo2: bldo2 {
				regulator-name = "axp2202-bldo2";
				regulator-min-microvolt = <500000>;
				regulator-max-microvolt = <3500000>;
				regulator-ramp-delay = <500>;
				regulator-enable-ramp-delay = <1000>;
				regulator-boot-on;
				regulator-always-on;
			};
			reg_bldo3: bldo3 {
				regulator-name = "axp2202-bldo3";
				regulator-min-microvolt = <500000>;
				regulator-max-microvolt = <3500000>;
				regulator-ramp-delay = <500>;
				regulator-enable-ramp-delay = <1000>;
			};
			reg_bldo4: bldo4 {
				regulator-name = "axp2202-bldo4";
				regulator-min-microvolt = <500000>;
				regulator-max-microvolt = <3500000>;
				regulator-ramp-delay = <500>;
				regulator-enable-ramp-delay = <1000>;
			};
			reg_cldo1: cldo1 {
				regulator-name = "axp2202-cldo1";
				regulator-min-microvolt = <500000>;
				regulator-max-microvolt = <3500000>;
				regulator-ramp-delay = <500>;
				regulator-enable-ramp-delay = <1000>;
				regulator-boot-on;
				regulator-always-on;
			};
			reg_cldo2: cldo2 {
				regulator-name = "axp2202-cldo2";
				regulator-min-microvolt = <500000>;
				regulator-max-microvolt = <3500000>;
				regulator-ramp-delay = <500>;
				regulator-enable-ramp-delay = <1000>;
			};
			reg_cldo3: cldo3 {
				regulator-name = "axp2202-cldo3";
				regulator-min-microvolt = <500000>;
				regulator-max-microvolt = <3500000>;
				regulator-ramp-delay = <500>;
				regulator-enable-ramp-delay = <1000>;
				regulator-boot-on;
				regulator-always-on;
			};
			reg_cldo4: cldo4 {
				regulator-name = "axp2202-cldo4";
				regulator-min-microvolt = <500000>;
				regulator-max-microvolt = <3500000>;
				regulator-ramp-delay = <500>;
				regulator-enable-ramp-delay = <1000>;
			};
			reg_cpusldo: cpusldo {
				/* cpus */
				regulator-name = "axp2202-cpusldo";
				regulator-min-microvolt = <500000>;
				regulator-max-microvolt = <1400000>;
				regulator-ramp-delay = <500>;
				regulator-enable-ramp-delay = <1000>;
				regulator-boot-on;
				regulator-always-on;
			};
			reg_vmid: vmid {
				regulator-name = "axp2202-vmid";
				regulator-enable-ramp-delay = <1000>;
			};
			reg_drivevbus: drivevbus {
				regulator-name = "axp2202-drivevbus";
				regulator-enable-ramp-delay = <1000>;
				drivevbusin-supply = <&reg_vmid>;
			};
		};

		virtual-dcdc1 {
			compatible = "xpower-vregulator,dcdc1";
			dcdc1-supply = <&reg_dcdc1>;
		};
		virtual-dcdc2 {
			compatible = "xpower-vregulator,dcdc2";
			dcdc2-supply = <&reg_dcdc2>;
		};
		virtual-dcdc3 {
			compatible = "xpower-vregulator,dcdc3";
			dcdc3-supply = <&reg_dcdc3>;
		};
		virtual-dcdc4 {
			compatible = "xpower-vregulator,dcdc4";
			dcdc4-supply = <&reg_dcdc4>;
		};
		virtual-rtcldo {
			compatible = "xpower-vregulator,rtcldo";
			rtcldo-supply = <&reg_rtcldo>;
		};
		virtual-aldo1 {
			compatible = "xpower-vregulator,aldo1";
			aldo1-supply = <&reg_aldo1>;
		};
		virtual-aldo2 {
			compatible = "xpower-vregulator,aldo2";
			aldo2-supply = <&reg_aldo2>;
		};
		virtual-aldo3 {
			compatible = "xpower-vregulator,aldo3";
			aldo3-supply = <&reg_aldo3>;
		};
		virtual-aldo4 {
			compatible = "xpower-vregulator,aldo4";
			aldo4-supply = <&reg_aldo4>;
		};
		virtual-bldo1 {
			compatible = "xpower-vregulator,bldo1";
			bldo1-supply = <&reg_bldo1>;
		};
		virtual-bldo2 {
			compatible = "xpower-vregulator,bldo2";
			bldo2-supply = <&reg_bldo2>;
		};
		virtual-bldo3 {
			compatible = "xpower-vregulator,bldo3";
			bldo3-supply = <&reg_bldo3>;
		};
		virtual-bldo4 {
			compatible = "xpower-vregulator,bldo4";
			bldo4-supply = <&reg_bldo4>;
		};
		virtual-cldo1 {
			compatible = "xpower-vregulator,cldo1";
			cldo1-supply = <&reg_cldo1>;
		};
		virtual-cldo2 {
			compatible = "xpower-vregulator,cldo2";
			cldo2-supply = <&reg_cldo2>;
		};
		virtual-cldo3 {
			compatible = "xpower-vregulator,cldo3";
			cldo3-supply = <&reg_cldo3>;
		};
		virtual-cldo4 {
			compatible = "xpower-vregulator,cldo4";
			cldo4-supply = <&reg_cldo4>;
		};
		virtual-cpusldo {
			compatible = "xpower-vregulator,cpusldo";
			cpusldo-supply = <&reg_cpusldo>;
		};
		virtual-drivevbus {
			compatible = "xpower-vregulator,drivevbus";
			drivevbus-supply = <&reg_drivevbus>;
		};
		axp_gpio0: axp_gpio@0 {
			gpio-controller;
			#size-cells = <0>;
			#gpio-cells = <6>;
			status = "okay";
		};
	};
};

/{
	axp2202_parameter:axp2202-parameter {
		select = "battery-model";

		battery-model {
			parameter = /bits/ 8 <0x01 0xf5 0x40 0x00 0x1b 0x1e 0x28 0x0f
				0x0c 0x1e 0x32 0x02 0x14 0x05 0x0a 0x04
				0x74 0xfb 0xc8 0x0d 0x43 0x10 0xcc 0xfb
				0x46 0x01 0xea 0x14 0x10 0x06 0xcc 0x06
				0x9d 0x0b 0x63 0x0f 0xf4 0x0f 0x94 0x0a
				0x4f 0x0e 0xf4 0x0e 0xeb 0x04 0xdd 0x04
				0xd1 0x09 0xc7 0x0e 0xb9 0x0e 0xb6 0x09
				0xae 0x0e 0x97 0x0e 0x97 0x04 0x86 0x04
				0x73 0x09 0x69 0x0e 0x60 0x0e 0x1e 0x08
				0x21 0x56 0x26 0x20 0x16 0x04 0x0b 0x00
				0xc5 0x98 0x7e 0x66 0x4e 0x44 0x38 0x1a
				0x12 0x0a 0xf6 0x00 0x00 0xf6 0x00 0xf6
				0x00 0xfb 0x00 0x00 0xfb 0x00 0x00 0xfb
				0x00 0x00 0xf6 0x00 0x00 0xf6 0x00 0xf6
				0x00 0xfb 0x00 0x00 0xfb 0x00 0x00 0xfb
				0x00 0x00 0xf6 0x00 0x00 0xf6 0x00 0xf6>;
		};
	};
};

&s_twi1 {
	clock-frequency = <400000>;
	pinctrl-0 = <&s_twi1_pins_default>;
	pinctrl-1 = <&s_twi1_pins_sleep>;
	pinctrl-names = "default", "sleep";
	/* For stability and backwards compatibility, we recommend setting 'twi_drv_used' to 1 */
	twi_drv_used = <1>;
	/* twi-supply = <&reg_bldo2>; */
	status = "disabled";
};

&s_twi2 {
	clock-frequency = <400000>;
	pinctrl-0 = <&s_twi2_pins_default>;
	pinctrl-1 = <&s_twi2_pins_sleep>;
	pinctrl-names = "default", "sleep";
	/* For stability and backwards compatibility, we recommend setting 'twi_drv_used' to 1 */
	twi_drv_used = <1>;
	/* twi-supply = <&reg_aldo3>; */
	status = "disabled";
};

/*
 * usb_port_type: usb mode. 0-device, 1-host, 2-otg.
 * usb_detect_type: usb hotplug detect mode. 0-none, 1-vbus/id detect, 2-pmu detect, 3-tcpm detect.
 * usb_detect_mode: 0-thread scan, 1-id gpio interrupt, 2-pmu notify.
 * usb_id_gpio: gpio for id detect.
 * usb_det_vbus_gpio: gpio for id detect. gpio or "axp_ctrl".
 * usb_wakeup_suspend: 0-SUPER_STANDBY, 1-USB_STANDBY.
 */
&usbc0 {
	device_type = "usbc0";
	usb_port_type = <0x2>;
	usb_detect_type = <0x1>;
	usb_detect_mode = <0x0>;
	usb_id_gpio = <&pio PH 14 GPIO_ACTIVE_HIGH>;
	enable-active-high;
	usb_det_vbus_gpio = <&r_pio PL 10 GPIO_ACTIVE_HIGH>;
	enable-active-high;
	usb_regulator_io = "nocare";
	usb_wakeup_suspend = <0>;
	usb_luns = <3>;
	usb_serial_unique = <0>;
	usb_serial_number = "20080411";
	rndis_wceis = <1>;
	status = "okay";
};

&udc {
	status = "okay";
};

&ehci0 {
	drvvbus-supply = <&reg_usb0_vbus>;
	status = "okay";
};

&ohci0 {
	drvvbus-supply = <&reg_usb0_vbus>;
	status = "okay";
};

&usbc1 {
	device_type = "usbc1";
	usb_regulator_io = "nocare";
	usb_wakeup_suspend = <0>;
	status = "okay";
};

&ehci1 {
	drvvbus-supply = <&reg_usb1_vbus>;
	status = "okay";
};

&ohci1 {
	drvvbus-supply = <&reg_usb1_vbus>;
	status = "okay";
};

&u2phy {
	status = "okay";
};

// &lvds0 {
// 	status = "okay";
// 	dual-channel = <0>;
// 	pinctrl-0 = <&lvds0_pins_a>;
// 	pinctrl-1 = <&lvds0_pins_b>;
// 	pinctrl-names = "active","sleep";
// 	ports {
// 		port@1 {
// 			reg = <1>;
// 			lvds_panel_out: endpoint@0 {
// 				reg = <0>;
// 				remote-endpoint = <&lvds_panel_in>;
// 			};
// 		};
// 	};
// };

&rgb0 {
	status = "disabled";
	pinctrl-0 = <&rgb0_24pins_a>;
	pinctrl-1 = <&rgb0_24pins_b>;
	pinctrl-names = "active","sleep";
	ports {
		port@1 {
			reg = <1>;
			rgb0_panel_out: endpoint@0 {
				reg = <0>;
				remote-endpoint = <&rgb0_panel_in>;
			};
		};
	};
};

&dsi0 {
	status = "okay";
	pinctrl-0 = <&dsi0_4lane_pins_a>;
	pinctrl-1 = <&dsi0_4lane_pins_b>;
	pinctrl-names = "active","sleep";
	ports {
		dsi1_out: port@1{
			dsi_out_panel: endpoint {
				remote-endpoint = <&panel_in>;
			};
		};
	};
	panel: panel@0 {
		compatible = "allwinner,virtual-panel";
		status = "okay";
		reg = <0>;
		ports {
			panel_in: port@0 {
				reg = <0>;
				panel_input: endpoint@0 {
					reg = <0>;
					remote-endpoint = <&dsi_out_panel>;
				};
			};
			panel_out: port@1 {
				reg = <1>;
				panel_output_0: endpoint@0 {
					reg = <0>;
					remote-endpoint = <&panel0_in>;
				};
			};
		};
	};
};


&dsi0combophy {
	status = "okay";
};

&rfkill {
	compatible = "allwinner,sunxi-rfkill";
	chip_en  = <&r_pio PM 1 GPIO_ACTIVE_HIGH>;
	power_en = <&r_pio PL 11 GPIO_ACTIVE_HIGH>;
	pinctrl-0;
	pinctrl-names;
	status = "okay";

	/* wlan session */
	wlan {
		compatible    = "allwinner,sunxi-wlan";
		clocks;
		clock-names;
		wlan_power    = "axp2202-aldo3", "axp2202-bldo1", "axp2202-bldo2"; /* vcc-pl/vcc-pg/vcc-pm */
		wlan_power_vol= <3300000>, <1800000>, <1800000>;
		wlan_busnum   = <0x1>;
		wlan_regon    = <&r_pio PM 5 GPIO_ACTIVE_HIGH>;
		wlan_hostwake = <&r_pio PM 0 GPIO_ACTIVE_HIGH>;
		wakeup-source;
	};

	/* bt session */
	bt {
		compatible    = "allwinner,sunxi-bt";
		clocks;
		clock-names;
		bt_power    = "axp2202-aldo3", "axp2202-bldo1", "axp2202-bldo2"; /* vcc-pl/vcc-pg/vcc-pm */
		bt_power_vol= <3300000>, <1800000>, <1800000>;
		bt_rst_n      = <&r_pio PM 2 GPIO_ACTIVE_LOW>;
	};
};


&de {
	chn_cfg_mode = <0>;
	status = "okay";
};

&vo0 {
	status = "okay";
};

&dlcd0 {
	status = "okay";
};

&addr_mgt {
	compatible     = "allwinner,sunxi-addr_mgt";
	type_addr_wifi = <0x0>;
	type_addr_bt   = <0x0>;
	type_addr_eth  = <0x0>;
	status         = "okay";
};

&btlpm {
	compatible  = "allwinner,sunxi-btlpm";
	uart_index  = <0x1>;
	bt_wake     = <&r_pio PM 3 GPIO_ACTIVE_HIGH>;
	bt_hostwake = <&r_pio PM 4 GPIO_ACTIVE_HIGH>;
	wakeup-source;
	status      = "okay";
};

&spi1 {
	pinctrl-0 = <&spi1_pins_default &spi1_pins_cs>;
	pinctrl-1 = <&spi1_pins_sleep>;
	pinctrl-names = "default", "sleep";
	sunxi,spi-bus-mode = <SUNXI_SPI_BUS_MASTER>;
	sunxi,spi-cs-mode = <SUNXI_SPI_CS_AUTO>;
	status = "disabled";

	spidev@0 {
		compatible = "rohm,dh2228fv";
		reg = <0x0>;
		spi-max-frequency = <100000000>;
		spi-rx-bus-width = <1>;
		spi-tx-bus-width = <1>;
		status = "disabled";
	};
};

&ir_rx {
	pinctrl-names = "default", "sleep";
	pinctrl-0 = <&irrx_pins_default>;
	pinctrl-1 = <&irrx_pins_sleep>;
	status = "disabled";
};

&ir_tx {
	pinctrl-names = "default", "sleep";
	pinctrl-0 = <&irtx_pins_default>;
	pinctrl-1 = <&irtx_pins_sleep>;
	status = "disabled";
};

&s_ir_rx {
	pinctrl-names = "default", "sleep";
	pinctrl-0 = <&s_irrx_pins_default>;
	pinctrl-1 = <&s_irrx_pins_default>;
	status = "disabled";
};

/* audio dirver module -> audio codec */
&codec {
	tx-hub-en;
	rx-sync-en;

	dac-vol		= <63>;		/* default value:63 range:0->63 */
	dacl-vol	= <160>;	/* default value:160 range:0->255 */
	dacr-vol	= <160>;	/* default value:160 range:0->255 */
	adc1-vol	= <160>;	/* default value:160 range:0->255 */
	adc2-vol	= <160>;	/* default value:160 range:0->255 */
	lineout-gain	= <31>;		/* default value:31 range:0->31 */
	hpout-gain	= <7>;		/* default value:7 range:0->7 */
	adc1-gain	= <31>;		/* default value:31 range:0->31 */
	adc2-gain	= <31>;		/* default value:31 range:0->31 */

	avcc-external;
	avcc-supply	= <&reg_aldo4>;
	avcc-vol	= <1800000>;
	vdd-external;
	vdd-supply	= <&reg_cldo3>;
	vdd-vol		= <3300000>;
	cpvin-external;
	cpvin-supply	= <&reg_cldo1>;
	cpvin-vol	= <1800000>;

	pa-pin-max	= <1>;
	pa-pin-0	= <&pio PH 6 GPIO_ACTIVE_HIGH>;
	pa-pin-level-0	= <1>;
	pa-pin-msleep-0	= <0>;

	jack-det-level		= <0>;
	jack-det-threshold	= <8>;
	jack-det-debouce	= <0>; /* optional value range:0->15 */

	/* extcon	        = <&usb_power_supply>;
	 * jack-swpin-max	= <3>;
	 * jack-swpin-0		= <&pio PH 8 GPIO_ACTIVE_HIGH>;
	 * jack-swpin-1		= <&pio PH 15 GPIO_ACTIVE_HIGH>;
	 * jack-swpin-2		= <&pio PH 11 GPIO_ACTIVE_HIGH>;
	 * jack-mode-off	= <0xf 0 0>;
	 * jack-mode-usb	= <0xf 1 1>;
	 * jack-mode-hp		= <0xf 1 0>;
	 * jack-mode-micn	= <1 0xf 0xf>;
	 * jack-mode-mici	= <0 0xf 0xf>;
	 * jack-det-level	= <1>;
	 * jack-det-threshold   = <8>;
	 * jack-det-debouce-tim = <250>;
	 */
	/* jack-key-det-voltage = <min max> */
	jack-key-det-voltage-hook	= <0 0>;
	jack-key-det-voltage-up		= <2 2>;
	jack-key-det-voltage-down	= <4 5>;
	jack-key-det-voltage-voice	= <1 1>;

	/* sdbp - headset detective based on headphone
	 *
	 * "jack-sdbp-method"
	 * 0 - Disable jack sdbp.
	 * 1 - Keep detecting by enable hmbias to trigger interupt.
	 * 2 - Keep detecting by hrtime interupt to read mic-pin voltage.
	 *
	 * "jack-sdbp-scan-single-time" (if defined "jack-sdbp-method")
	 * 1. The unit is ms.
	 * 2. The length of time between each detection.
	 * 3. The value must greater than 1000.
	 */
	jack-sdbp-method = <0>;
	jack-sdbp-scan-single-time = <1000>;

	status = "okay";
};

&codec_plat {
	status = "okay";
};

&codec_mach {
	status = "okay";
	soundcard-mach,cpu {
		sound-dai = <&codec_plat>;
	};
	soundcard-mach,codec {
		sound-dai = <&codec>;
	};
};

/* audio dirver module -> owa */
&owa_plat {
	pinctrl-used;
	pinctrl-names	= "default","sleep";
	pinctrl-0	= <&owa_pins_a>;
	pinctrl-1	= <&owa_pins_b>;
	tx-hub-en;
	status		= "disabled";
};

&owa_mach {
	status		= "disabled";
	soundcard-mach,cpu {
		sound-dai = <&owa_plat>;
	};
	soundcard-mach,codec {
	};
};

/* audio dirver module -> DMIC */
&dmic_plat {
	rx-chmap	= <0x76543210>;
	data-vol	= <0xB0>;
	rxdelaytime	= <0>;
	pinctrl-used;
	pinctrl-names	= "default","sleep";
	pinctrl-0	= <&dmic_pins_a>;
	pinctrl-1	= <&dmic_pins_b>;
	rx-sync-en;
	status		= "disabled";
};

&dmic_mach {
	status		= "disabled";
	soundcard-mach,cpu {
		sound-dai = <&dmic_plat>;
	};
	soundcard-mach,codec {
	};
};

/* audio dirver module -> I2S/PCM */
&i2s0_plat {
	tdm-num		= <0>;

	/* "tx-pin"
	 * 1. tx pin enable setting.
	 * 2. we can set it like tx_pin = <3 0> - enable tx_pin0 and tx_pin3.
	 *
	 * "rx-pin"
	 * 1. rx pin enable setting.
	 * 2. we can set it like rx_pin = <1 2> - enable rx_pin1 and rx_pin2.
	 *
	 * "tx-pin-chmap"
	 * 1. tx pin channel map setting.
	 * 2. the subscript of value corresponds to the channel number.
	 * 3. the value corresponds to slot number.
	 * 4. we can use it like tx-pin1-chmap = <1 2 ... 15> to set pin1 channel map.
	 * 5. if enabled the pin, but not set "tx-pin-chmap", default set <0 1 2 ...>.
	 * 6. if the count of value is less than 16, then missing member will be set 0.
	 *
	 * rxfifo map
	 * 1. "rxfifo-pinmap" - set the corresponding pin.
	 * 2. "rxfifo-chmap" - set the corresponding slot.
	 * 3. we can use it like rxfifo-pinmap = <0 1 2>; rxfifo-chmap = <1 2 14>; to set rxfifo map.
	 * 4. the count of value of "rxfifo-pinmap" can != the count of value of "rxfifo-pinmap",
	 *    then missing member would be set 0.
	 */
	tx-pin		= <0>;
	rx-pin		= <0>;
	/* tx-pin0-chmap = <0 1 5>; */
	/* rxfifo-pinmap = <0 0>; */
	/* rxfifo-chmap = <0 1>; */

	/* pinctrl-used; */
	/* pinctrl-names	= "default","sleep"; */
	/* pinctrl-0	= <&i2s0_pins_a &i2s0_pins_b &i2s0_pins_c &i2s0_pins_d>; */
	/* pinctrl-1	= <&i2s0_pins_e>; */
	tx-hub-en;
	rx-sync-en;
	status		= "disabled";
};

&i2s0_mach {
	soundcard-mach,format		= "i2s";
	soundcard-mach,frame-master	= <&i2s0_cpu>;
	soundcard-mach,bitclock-master	= <&i2s0_cpu>;
	/* soundcard-mach,frame-inversion; */
	/* soundcard-mach,bitclock-inversion; */
	soundcard-mach,slot-num		= <2>;
	soundcard-mach,slot-width	= <32>;
	soundcard-mach,capture-only;
	status		= "disabled";
	i2s0_cpu: soundcard-mach,cpu {
		sound-dai = <&i2s0_plat>;
		/* note: pll freq = 24.576M or 22.5792M * pll-fs */
		soundcard-mach,pll-fs	= <1>;
		/* note:
		 * "mclk-fs"
		 * if not defined it or equal to 0, disable mclk.
		 *
		 * "mclk-fp" (if defined "mclk-fs")
		 * 1. if not defined "mclk-fp", mclk_freq = mclk-fs * sample_rate;
		 * 2. if defined "mclk-fp" but no value, mclk_freq = mclk-fs * 11.2896M or 12.288M;
		 * 3. if defined "mclk-fp" with 2 value, like: mclk-fp = <val1 val2>;
		 *    it means: mclk_freq(44.1k fp) = mclk-fs * val1;
		 *              mclk_freq(48k fp)   = mclk-fs * val2.
		 */
		soundcard-mach,mclk-fs	= <1>;
		soundcard-mach,mclk-fp	= <11289600 12288000>;
	};
	i2s0_codec: soundcard-mach,codec {
		sound-dai               = <&ac107>;
		soundcard-mach,pll-fs   = <1>;
	};
};

&i2s1_plat {
	tdm-num		= <1>;
	tx-pin		= <0>;
	rx-pin		= <0>;
	/* pinctrl-used; */
	/* pinctrl-names= "default","sleep"; */
	/* pinctrl-0	= <&i2s1_pins_a &i2s1_pins_b &i2s1_pins_c &i2s1_pins_d>; */
	/* pinctrl-1	= <&i2s1_pins_e>; */
	tx-hub-en;
	rx-sync-en;
	status		= "disabled";
};

&i2s1_mach {
	soundcard-mach,format		= "i2s";
	soundcard-mach,frame-master	= <&i2s1_cpu>;
	soundcard-mach,bitclock-master	= <&i2s1_cpu>;
	/* soundcard-mach,frame-inversion; */
	/* soundcard-mach,bitclock-inversion; */
	soundcard-mach,slot-num		= <2>;
	soundcard-mach,slot-width	= <32>;
	status		= "disabled";
	i2s1_cpu: soundcard-mach,cpu {
		sound-dai = <&i2s1_plat>;
		soundcard-mach,pll-fs	= <1>;
		soundcard-mach,mclk-fs	= <0>;
	};
	i2s1_codec: soundcard-mach,codec {
	};
};

&i2s2_plat {
	tdm-num		= <2>;
	tx-pin		= <0>;
	rx-pin		= <0>;
	/* pinctrl-used; */
	/* pinctrl-names= "default","sleep"; */
	/* pinctrl-0	= <&i2s2_pins_a &i2s2_pins_b &i2s2_pins_c &i2s2_pins_d>; */
	/* pinctrl-1	= <&i2s2_pins_e>; */
	tx-hub-en;
	rx-sync-en;
	status		= "disabled";
};

&i2s2_mach {
	soundcard-mach,format		= "i2s";
	soundcard-mach,frame-master	= <&i2s2_cpu>;
	soundcard-mach,bitclock-master	= <&i2s2_cpu>;
	/* soundcard-mach,frame-inversion; */
	/* soundcard-mach,bitclock-inversion; */
	soundcard-mach,slot-num		= <2>;
	soundcard-mach,slot-width	= <32>;
	status		= "disabled";
	i2s2_cpu: soundcard-mach,cpu {
		sound-dai = <&i2s2_plat>;
		soundcard-mach,pll-fs	= <1>;
		soundcard-mach,mclk-fs	= <0>;
	};
	i2s2_codec: soundcard-mach,codec {
	};
};

&i2s3_plat {
	tdm-num		= <3>;
	tx-pin		= <0>;
	rx-pin		= <0>;
	/* pinctrl-used; */
	/* pinctrl-names= "default","sleep"; */
	/* pinctrl-0	= <&i2s3_pins_a &i2s3_pins_b &i2s3_pins_c &i2s3_pins_d>; */
	/* pinctrl-1	= <&i2s3_pins_e>; */
	tx-hub-en;
	rx-sync-en;
	status		= "disabled";
};

&i2s3_mach {
	soundcard-mach,format		= "i2s";
	soundcard-mach,frame-master	= <&i2s3_cpu>;
	soundcard-mach,bitclock-master	= <&i2s3_cpu>;
	/* soundcard-mach,frame-inversion; */
	/* soundcard-mach,bitclock-inversion; */
	soundcard-mach,slot-num		= <2>;
	soundcard-mach,slot-width	= <32>;
	status		= "disabled";
	i2s3_cpu: soundcard-mach,cpu {
		sound-dai = <&i2s3_plat>;
		soundcard-mach,pll-fs	= <1>;
		soundcard-mach,mclk-fs	= <0>;
	};
	i2s3_codec: soundcard-mach,codec {
	};
};

&cpu0 {
	cpu-supply = <&reg_dcdc1>;
};

&cpu4 {
	cpu-supply = <&reg_axp1530_dcdc2>;
};

&cpu6 {
	cpu-supply = <&reg_axp1530_dcdc1>;
};

&gpu {
	gpu_idle = <1>;
	dvfs_status = <1>;
	mali-supply = <&reg_axp1530_dcdc3>;
};

